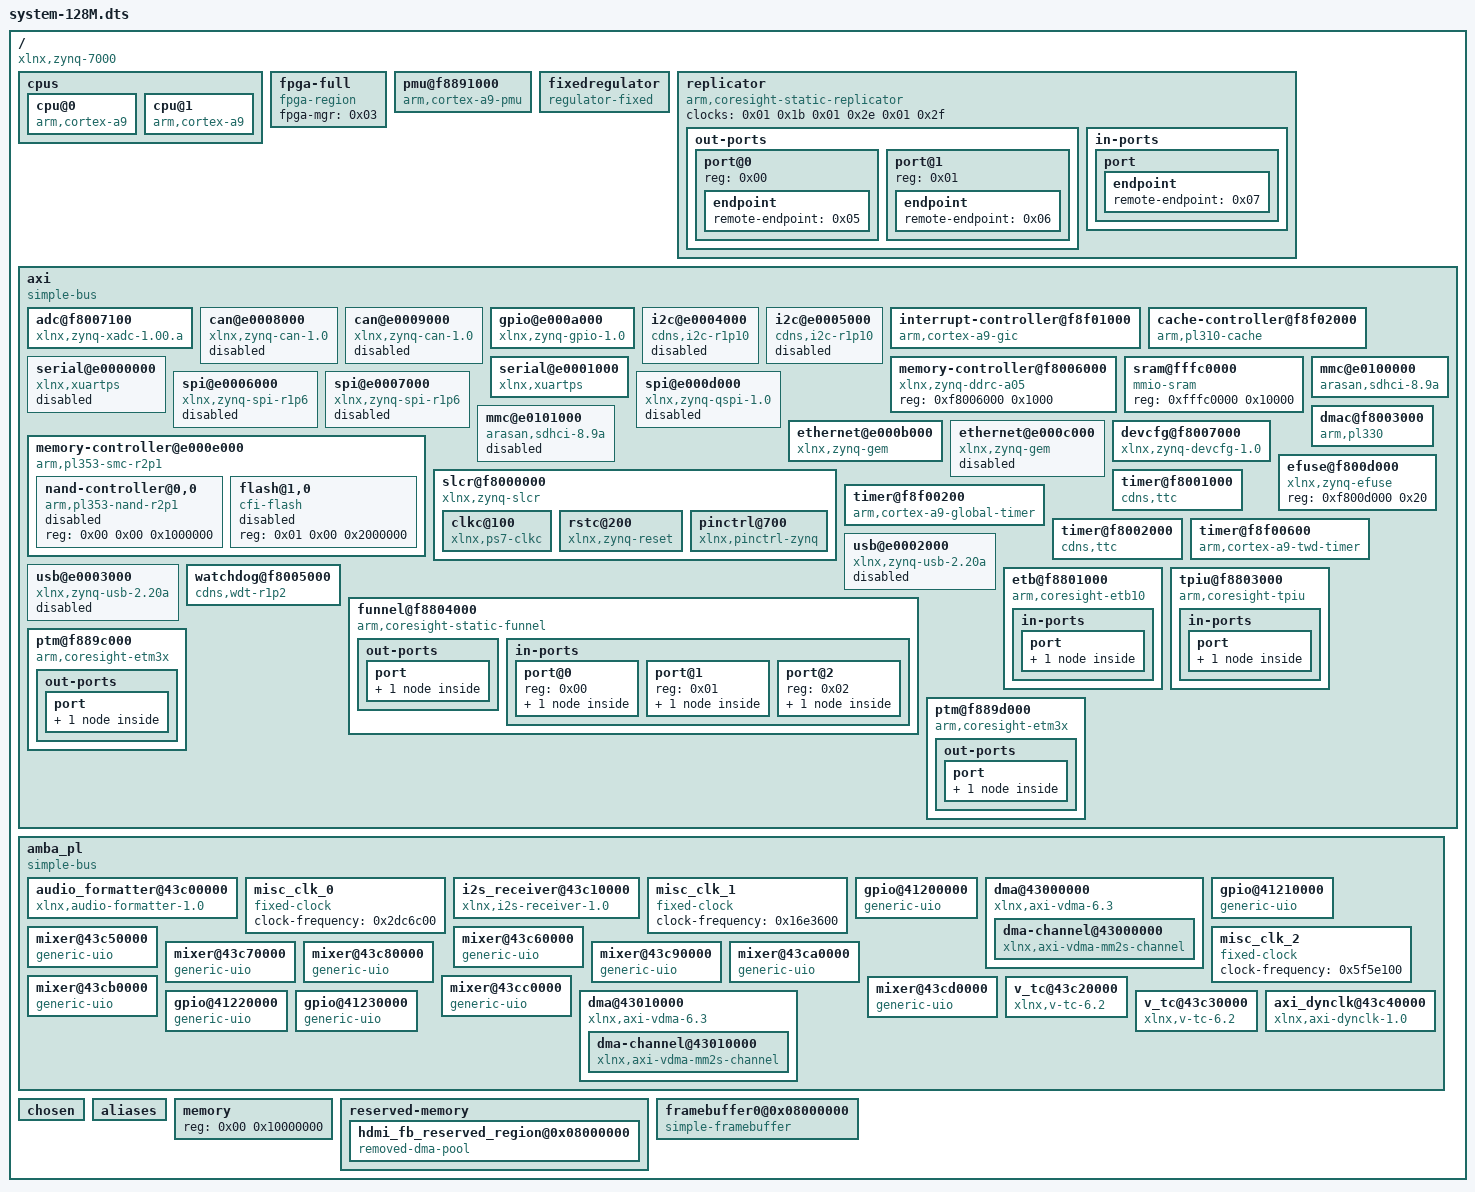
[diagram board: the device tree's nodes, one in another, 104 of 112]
/dts-v1/;

/ {
	#address-cells = <0x01>;
	#size-cells = <0x01>;
	compatible = "xlnx,zynq-7000";

	cpus {
		#address-cells = <0x01>;
		#size-cells = <0x00>;

		cpu@0 {
			compatible = "arm,cortex-a9";
			device_type = "cpu";
			reg = <0x00>;
			clocks = <0x01 0x03>;
			clock-latency = <0x3e8>;
			cpu0-supply = <0x02>;
			operating-points = <0xa2c2a 0xf4240 0x51615 0xf4240>;
			phandle = <0x0e>;
		};

		cpu@1 {
			compatible = "arm,cortex-a9";
			device_type = "cpu";
			reg = <0x01>;
			clocks = <0x01 0x03>;
			phandle = <0x10>;
		};
	};

	fpga-full {
		compatible = "fpga-region";
		fpga-mgr = <0x03>;
		#address-cells = <0x01>;
		#size-cells = <0x01>;
		ranges;
		phandle = <0x17>;
	};

	pmu@f8891000 {
		compatible = "arm,cortex-a9-pmu";
		interrupts = <0x00 0x05 0x04 0x00 0x06 0x04>;
		interrupt-parent = <0x04>;
		reg = <0xf8891000 0x1000 0xf8893000 0x1000>;
	};

	fixedregulator {
		compatible = "regulator-fixed";
		regulator-name = "VCCPINT";
		regulator-min-microvolt = <0xf4240>;
		regulator-max-microvolt = <0xf4240>;
		regulator-boot-on;
		regulator-always-on;
		phandle = <0x02>;
	};

	replicator {
		compatible = "arm,coresight-static-replicator";
		clocks = <0x01 0x1b 0x01 0x2e 0x01 0x2f>;
		clock-names = "apb_pclk\0dbg_trc\0dbg_apb";

		out-ports {
			#address-cells = <0x01>;
			#size-cells = <0x00>;

			port@0 {
				reg = <0x00>;

				endpoint {
					remote-endpoint = <0x05>;
					phandle = <0x0a>;
				};
			};

			port@1 {
				reg = <0x01>;

				endpoint {
					remote-endpoint = <0x06>;
					phandle = <0x09>;
				};
			};
		};

		in-ports {

			port {

				endpoint {
					remote-endpoint = <0x07>;
					phandle = <0x0b>;
				};
			};
		};
	};

	axi {
		u-boot,dm-pre-reloc;
		compatible = "simple-bus";
		#address-cells = <0x01>;
		#size-cells = <0x01>;
		interrupt-parent = <0x04>;
		ranges;
		phandle = <0x18>;

		adc@f8007100 {
			compatible = "xlnx,zynq-xadc-1.00.a";
			reg = <0xf8007100 0x20>;
			interrupts = <0x00 0x07 0x04>;
			interrupt-parent = <0x04>;
			clocks = <0x01 0x0c>;
			phandle = <0x19>;
		};

		can@e0008000 {
			compatible = "xlnx,zynq-can-1.0";
			status = "disabled";
			clocks = <0x01 0x13 0x01 0x24>;
			clock-names = "can_clk\0pclk";
			reg = <0xe0008000 0x1000>;
			interrupts = <0x00 0x1c 0x04>;
			interrupt-parent = <0x04>;
			tx-fifo-depth = <0x40>;
			rx-fifo-depth = <0x40>;
			phandle = <0x1a>;
		};

		can@e0009000 {
			compatible = "xlnx,zynq-can-1.0";
			status = "disabled";
			clocks = <0x01 0x14 0x01 0x25>;
			clock-names = "can_clk\0pclk";
			reg = <0xe0009000 0x1000>;
			interrupts = <0x00 0x33 0x04>;
			interrupt-parent = <0x04>;
			tx-fifo-depth = <0x40>;
			rx-fifo-depth = <0x40>;
			phandle = <0x1b>;
		};

		gpio@e000a000 {
			compatible = "xlnx,zynq-gpio-1.0";
			#gpio-cells = <0x02>;
			clocks = <0x01 0x2a>;
			gpio-controller;
			interrupt-controller;
			#interrupt-cells = <0x02>;
			interrupt-parent = <0x04>;
			interrupts = <0x00 0x14 0x04>;
			reg = <0xe000a000 0x1000>;
			emio-gpio-width = <0x40>;
			gpio-mask-high = <0x00>;
			gpio-mask-low = <0x5600>;
			phandle = <0x1c>;
		};

		i2c@e0004000 {
			compatible = "cdns,i2c-r1p10";
			status = "disabled";
			clocks = <0x01 0x26>;
			interrupt-parent = <0x04>;
			interrupts = <0x00 0x19 0x04>;
			reg = <0xe0004000 0x1000>;
			#address-cells = <0x01>;
			#size-cells = <0x00>;
			phandle = <0x1d>;
		};

		i2c@e0005000 {
			compatible = "cdns,i2c-r1p10";
			status = "disabled";
			clocks = <0x01 0x27>;
			interrupt-parent = <0x04>;
			interrupts = <0x00 0x30 0x04>;
			reg = <0xe0005000 0x1000>;
			#address-cells = <0x01>;
			#size-cells = <0x00>;
			phandle = <0x1e>;
		};

		interrupt-controller@f8f01000 {
			compatible = "arm,cortex-a9-gic";
			#interrupt-cells = <0x03>;
			interrupt-controller;
			reg = <0xf8f01000 0x1000 0xf8f00100 0x100>;
			num_cpus = <0x02>;
			num_interrupts = <0x60>;
			phandle = <0x04>;
		};

		cache-controller@f8f02000 {
			compatible = "arm,pl310-cache";
			reg = <0xf8f02000 0x1000>;
			interrupts = <0x00 0x02 0x04>;
			arm,data-latency = <0x03 0x02 0x02>;
			arm,tag-latency = <0x02 0x02 0x02>;
			cache-unified;
			cache-level = <0x02>;
			phandle = <0x1f>;
		};

		memory-controller@f8006000 {
			compatible = "xlnx,zynq-ddrc-a05";
			reg = <0xf8006000 0x1000>;
			phandle = <0x20>;
		};

		sram@fffc0000 {
			compatible = "mmio-sram";
			reg = <0xfffc0000 0x10000>;
			phandle = <0x21>;
		};

		serial@e0000000 {
			compatible = "xlnx,xuartps\0cdns,uart-r1p8";
			status = "disabled";
			clocks = <0x01 0x17 0x01 0x28>;
			clock-names = "uart_clk\0pclk";
			reg = <0xe0000000 0x1000>;
			interrupts = <0x00 0x1b 0x04>;
			phandle = <0x22>;
		};

		serial@e0001000 {
			compatible = "xlnx,xuartps\0cdns,uart-r1p8";
			status = "okay";
			clocks = <0x01 0x18 0x01 0x29>;
			clock-names = "uart_clk\0pclk";
			reg = <0xe0001000 0x1000>;
			interrupts = <0x00 0x32 0x04>;
			cts-override;
			device_type = "serial";
			port-number = <0x00>;
			phandle = <0x23>;
		};

		spi@e0006000 {
			compatible = "xlnx,zynq-spi-r1p6";
			reg = <0xe0006000 0x1000>;
			status = "disabled";
			interrupt-parent = <0x04>;
			interrupts = <0x00 0x1a 0x04>;
			clocks = <0x01 0x19 0x01 0x22>;
			clock-names = "ref_clk\0pclk";
			#address-cells = <0x01>;
			#size-cells = <0x00>;
			phandle = <0x24>;
		};

		spi@e0007000 {
			compatible = "xlnx,zynq-spi-r1p6";
			reg = <0xe0007000 0x1000>;
			status = "disabled";
			interrupt-parent = <0x04>;
			interrupts = <0x00 0x31 0x04>;
			clocks = <0x01 0x1a 0x01 0x23>;
			clock-names = "ref_clk\0pclk";
			#address-cells = <0x01>;
			#size-cells = <0x00>;
			phandle = <0x25>;
		};

		spi@e000d000 {
			clock-names = "ref_clk\0pclk";
			clocks = <0x01 0x0a 0x01 0x2b>;
			compatible = "xlnx,zynq-qspi-1.0";
			status = "disabled";
			interrupt-parent = <0x04>;
			interrupts = <0x00 0x13 0x04>;
			reg = <0xe000d000 0x1000>;
			#address-cells = <0x01>;
			#size-cells = <0x00>;
			phandle = <0x26>;
		};

		ethernet@e000b000 {
			compatible = "xlnx,zynq-gem\0cdns,zynq-gem\0cdns,gem";
			reg = <0xe000b000 0x1000>;
			status = "okay";
			interrupts = <0x00 0x16 0x04>;
			clocks = <0x01 0x1e 0x01 0x1e 0x01 0x0d>;
			clock-names = "pclk\0hclk\0tx_clk";
			#address-cells = <0x01>;
			#size-cells = <0x00>;
			phy-mode = "gmii";
			xlnx,ptp-enet-clock = <0x69f6bcb>;
			local-mac-address = [00 0a 35 00 1e 53];
			phandle = <0x27>;
		};

		ethernet@e000c000 {
			compatible = "xlnx,zynq-gem\0cdns,zynq-gem\0cdns,gem";
			reg = <0xe000c000 0x1000>;
			status = "disabled";
			interrupts = <0x00 0x2d 0x04>;
			clocks = <0x01 0x1f 0x01 0x1f 0x01 0x0e>;
			clock-names = "pclk\0hclk\0tx_clk";
			#address-cells = <0x01>;
			#size-cells = <0x00>;
			phandle = <0x28>;
		};

		memory-controller@e000e000 {
			compatible = "arm,pl353-smc-r2p1\0arm,primecell";
			reg = <0xe000e000 0x1000>;
			status = "okay";
			clock-names = "memclk\0apb_pclk";
			clocks = <0x01 0x0b 0x01 0x2c>;
			ranges = <0x00 0x00 0xe1000000 0x1000000 0x01 0x00 0xe2000000 0x2000000 0x02 0x00 0xe4000000 0x2000000>;
			#address-cells = <0x02>;
			#size-cells = <0x01>;
			interrupt-parent = <0x04>;
			interrupts = <0x00 0x12 0x04>;
			phandle = <0x29>;

			nand-controller@0,0 {
				compatible = "arm,pl353-nand-r2p1";
				reg = <0x00 0x00 0x1000000>;
				status = "disabled";
				#address-cells = <0x01>;
				#size-cells = <0x00>;
				phandle = <0x2a>;
			};

			flash@1,0 {
				status = "disabled";
				compatible = "cfi-flash";
				reg = <0x01 0x00 0x2000000>;
				#address-cells = <0x01>;
				#size-cells = <0x01>;
				phandle = <0x2b>;
			};
		};

		mmc@e0100000 {
			compatible = "arasan,sdhci-8.9a";
			status = "okay";
			clock-names = "clk_xin\0clk_ahb";
			clocks = <0x01 0x15 0x01 0x20>;
			interrupt-parent = <0x04>;
			interrupts = <0x00 0x18 0x04>;
			reg = <0xe0100000 0x1000>;
			xlnx,has-cd = <0x01>;
			xlnx,has-power = <0x00>;
			xlnx,has-wp = <0x00>;
			phandle = <0x2c>;
		};

		mmc@e0101000 {
			compatible = "arasan,sdhci-8.9a";
			status = "disabled";
			clock-names = "clk_xin\0clk_ahb";
			clocks = <0x01 0x16 0x01 0x21>;
			interrupt-parent = <0x04>;
			interrupts = <0x00 0x2f 0x04>;
			reg = <0xe0101000 0x1000>;
			phandle = <0x2d>;
		};

		slcr@f8000000 {
			u-boot,dm-pre-reloc;
			#address-cells = <0x01>;
			#size-cells = <0x01>;
			compatible = "xlnx,zynq-slcr\0syscon\0simple-mfd";
			reg = <0xf8000000 0x1000>;
			ranges;
			phandle = <0x08>;

			clkc@100 {
				u-boot,dm-pre-reloc;
				#clock-cells = <0x01>;
				compatible = "xlnx,ps7-clkc";
				fclk-enable = <0x07>;
				clock-output-names = "armpll\0ddrpll\0iopll\0cpu_6or4x\0cpu_3or2x\0cpu_2x\0cpu_1x\0ddr2x\0ddr3x\0dci\0lqspi\0smc\0pcap\0gem0\0gem1\0fclk0\0fclk1\0fclk2\0fclk3\0can0\0can1\0sdio0\0sdio1\0uart0\0uart1\0spi0\0spi1\0dma\0usb0_aper\0usb1_aper\0gem0_aper\0gem1_aper\0sdio0_aper\0sdio1_aper\0spi0_aper\0spi1_aper\0can0_aper\0can1_aper\0i2c0_aper\0i2c1_aper\0uart0_aper\0uart1_aper\0gpio_aper\0lqspi_aper\0smc_aper\0swdt\0dbg_trc\0dbg_apb";
				reg = <0x100 0x100>;
				ps-clk-frequency = <0x1fca055>;
				phandle = <0x01>;
			};

			rstc@200 {
				compatible = "xlnx,zynq-reset";
				reg = <0x200 0x48>;
				#reset-cells = <0x01>;
				syscon = <0x08>;
				phandle = <0x2e>;
			};

			pinctrl@700 {
				compatible = "xlnx,pinctrl-zynq";
				reg = <0x700 0x200>;
				syscon = <0x08>;
				phandle = <0x2f>;
			};
		};

		dmac@f8003000 {
			compatible = "arm,pl330\0arm,primecell";
			reg = <0xf8003000 0x1000>;
			interrupt-parent = <0x04>;
			interrupt-names = "abort\0dma0\0dma1\0dma2\0dma3\0dma4\0dma5\0dma6\0dma7";
			interrupts = <0x00 0x0d 0x04 0x00 0x0e 0x04 0x00 0x0f 0x04 0x00 0x10 0x04 0x00 0x11 0x04 0x00 0x28 0x04 0x00 0x29 0x04 0x00 0x2a 0x04 0x00 0x2b 0x04>;
			#dma-cells = <0x01>;
			#dma-channels = <0x08>;
			#dma-requests = <0x04>;
			clocks = <0x01 0x1b>;
			clock-names = "apb_pclk";
			phandle = <0x30>;
		};

		devcfg@f8007000 {
			compatible = "xlnx,zynq-devcfg-1.0";
			interrupt-parent = <0x04>;
			interrupts = <0x00 0x08 0x04>;
			reg = <0xf8007000 0x100>;
			clocks = <0x01 0x0c 0x01 0x0f 0x01 0x10 0x01 0x11 0x01 0x12>;
			clock-names = "ref_clk\0fclk0\0fclk1\0fclk2\0fclk3";
			syscon = <0x08>;
			phandle = <0x03>;
		};

		efuse@f800d000 {
			compatible = "xlnx,zynq-efuse";
			reg = <0xf800d000 0x20>;
			phandle = <0x31>;
		};

		timer@f8f00200 {
			compatible = "arm,cortex-a9-global-timer";
			reg = <0xf8f00200 0x20>;
			interrupts = <0x01 0x0b 0x301>;
			interrupt-parent = <0x04>;
			clocks = <0x01 0x04>;
			phandle = <0x32>;
		};

		timer@f8001000 {
			interrupt-parent = <0x04>;
			interrupts = <0x00 0x0a 0x04 0x00 0x0b 0x04 0x00 0x0c 0x04>;
			compatible = "cdns,ttc";
			clocks = <0x01 0x06>;
			reg = <0xf8001000 0x1000>;
			phandle = <0x33>;
		};

		timer@f8002000 {
			interrupt-parent = <0x04>;
			interrupts = <0x00 0x25 0x04 0x00 0x26 0x04 0x00 0x27 0x04>;
			compatible = "cdns,ttc";
			clocks = <0x01 0x06>;
			reg = <0xf8002000 0x1000>;
			phandle = <0x34>;
		};

		timer@f8f00600 {
			interrupt-parent = <0x04>;
			interrupts = <0x01 0x0d 0x301>;
			compatible = "arm,cortex-a9-twd-timer";
			reg = <0xf8f00600 0x20>;
			clocks = <0x01 0x04>;
			phandle = <0x35>;
		};

		usb@e0002000 {
			compatible = "xlnx,zynq-usb-2.20a\0chipidea,usb2";
			status = "disabled";
			clocks = <0x01 0x1c>;
			interrupt-parent = <0x04>;
			interrupts = <0x00 0x15 0x04>;
			reg = <0xe0002000 0x1000>;
			phy_type = "ulpi";
			phandle = <0x36>;
		};

		usb@e0003000 {
			compatible = "xlnx,zynq-usb-2.20a\0chipidea,usb2";
			status = "disabled";
			clocks = <0x01 0x1d>;
			interrupt-parent = <0x04>;
			interrupts = <0x00 0x2c 0x04>;
			reg = <0xe0003000 0x1000>;
			phy_type = "ulpi";
			phandle = <0x37>;
		};

		watchdog@f8005000 {
			clocks = <0x01 0x2d>;
			compatible = "cdns,wdt-r1p2";
			interrupt-parent = <0x04>;
			interrupts = <0x00 0x09 0x01>;
			reg = <0xf8005000 0x1000>;
			timeout-sec = <0x0a>;
			phandle = <0x38>;
		};

		etb@f8801000 {
			compatible = "arm,coresight-etb10\0arm,primecell";
			reg = <0xf8801000 0x1000>;
			clocks = <0x01 0x1b 0x01 0x2e 0x01 0x2f>;
			clock-names = "apb_pclk\0dbg_trc\0dbg_apb";

			in-ports {

				port {

					endpoint {
						remote-endpoint = <0x09>;
						phandle = <0x06>;
					};
				};
			};
		};

		tpiu@f8803000 {
			compatible = "arm,coresight-tpiu\0arm,primecell";
			reg = <0xf8803000 0x1000>;
			clocks = <0x01 0x1b 0x01 0x2e 0x01 0x2f>;
			clock-names = "apb_pclk\0dbg_trc\0dbg_apb";

			in-ports {

				port {

					endpoint {
						remote-endpoint = <0x0a>;
						phandle = <0x05>;
					};
				};
			};
		};

		funnel@f8804000 {
			compatible = "arm,coresight-static-funnel\0arm,primecell";
			reg = <0xf8804000 0x1000>;
			clocks = <0x01 0x1b 0x01 0x2e 0x01 0x2f>;
			clock-names = "apb_pclk\0dbg_trc\0dbg_apb";

			out-ports {

				port {

					endpoint {
						remote-endpoint = <0x0b>;
						phandle = <0x07>;
					};
				};
			};

			in-ports {
				#address-cells = <0x01>;
				#size-cells = <0x00>;

				port@0 {
					reg = <0x00>;

					endpoint {
						remote-endpoint = <0x0c>;
						phandle = <0x0f>;
					};
				};

				port@1 {
					reg = <0x01>;

					endpoint {
						remote-endpoint = <0x0d>;
						phandle = <0x11>;
					};
				};

				port@2 {
					reg = <0x02>;

					endpoint {
						phandle = <0x39>;
					};
				};
			};
		};

		ptm@f889c000 {
			compatible = "arm,coresight-etm3x\0arm,primecell";
			reg = <0xf889c000 0x1000>;
			clocks = <0x01 0x1b 0x01 0x2e 0x01 0x2f>;
			clock-names = "apb_pclk\0dbg_trc\0dbg_apb";
			cpu = <0x0e>;

			out-ports {

				port {

					endpoint {
						remote-endpoint = <0x0f>;
						phandle = <0x0c>;
					};
				};
			};
		};

		ptm@f889d000 {
			compatible = "arm,coresight-etm3x\0arm,primecell";
			reg = <0xf889d000 0x1000>;
			clocks = <0x01 0x1b 0x01 0x2e 0x01 0x2f>;
			clock-names = "apb_pclk\0dbg_trc\0dbg_apb";
			cpu = <0x10>;

			out-ports {

				port {

					endpoint {
						remote-endpoint = <0x11>;
						phandle = <0x0d>;
					};
				};
			};
		};
	};

	amba_pl {
		#address-cells = <0x01>;
		#size-cells = <0x01>;
		compatible = "simple-bus";
		ranges;
		phandle = <0x3a>;

		audio_formatter@43c00000 {
			clock-names = "s_axi_lite_aclk\0s_axis_s2mm_aclk";
			clocks = <0x01 0x0f 0x12>;
			compatible = "xlnx,audio-formatter-1.0\0xlnx,audio-formatter-1.0";
			interrupt-names = "irq_s2mm";
			interrupt-parent = <0x04>;
			interrupts = <0x00 0x24 0x04>;
			reg = <0x43c00000 0x10000>;
			xlnx,include-mm2s = <0x00>;
			xlnx,include-s2mm = <0x01>;
			xlnx,max-num-channels-mm2s = <0x02>;
			xlnx,max-num-channels-s2mm = <0x02>;
			xlnx,mm2s-addr-width = <0x40>;
			xlnx,mm2s-async-clock = <0x01>;
			xlnx,mm2s-dataformat = <0x03>;
			xlnx,packing-mode-mm2s = <0x00>;
			xlnx,packing-mode-s2mm = <0x00>;
			xlnx,rx = <0x13>;
			xlnx,s2mm-addr-width = <0x40>;
			xlnx,s2mm-async-clock = <0x01>;
			xlnx,s2mm-dataformat = <0x01>;
			phandle = <0x15>;
		};

		misc_clk_0 {
			#clock-cells = <0x00>;
			clock-frequency = <0x2dc6c00>;
			compatible = "fixed-clock";
			phandle = <0x12>;
		};

		i2s_receiver@43c10000 {
			aud_mclk = <0x16e3600>;
			clock-names = "s_axi_ctrl_aclk\0aud_mclk\0m_axis_aud_aclk";
			clocks = <0x01 0x0f 0x14 0x12>;
			compatible = "xlnx,i2s-receiver-1.0\0xlnx,i2s-receiver-1.0";
			interrupt-names = "irq";
			interrupt-parent = <0x04>;
			interrupts = <0x00 0x23 0x04>;
			reg = <0x43c10000 0x10000>;
			xlnx,depth = <0x100>;
			xlnx,dwidth = <0x10>;
			xlnx,num-channels = <0x01>;
			xlnx,snd-pcm = <0x15>;
			phandle = <0x13>;
		};

		misc_clk_1 {
			#clock-cells = <0x00>;
			clock-frequency = <0x16e3600>;
			compatible = "fixed-clock";
			phandle = <0x14>;
		};

		gpio@41200000 {
			#gpio-cells = <0x02>;
			#interrupt-cells = <0x02>;
			clock-names = "s_axi_aclk";
			clocks = <0x01 0x0f>;
			compatible = "generic-uio";
			gpio-controller;
			interrupt-controller;
			interrupt-names = "ip2intc_irpt";
			interrupt-parent = <0x04>;
			interrupts = <0x00 0x22 0x04>;
			reg = <0x41200000 0x10000>;
			xlnx,all-inputs = <0x01>;
			xlnx,all-inputs-2 = <0x00>;
			xlnx,all-outputs = <0x00>;
			xlnx,all-outputs-2 = <0x00>;
			xlnx,dout-default = <0x00>;
			xlnx,dout-default-2 = <0x00>;
			xlnx,gpio-width = <0x01>;
			xlnx,gpio2-width = <0x20>;
			xlnx,interrupt-present = <0x01>;
			xlnx,is-dual = <0x00>;
			xlnx,tri-default = <0xffffffff>;
			xlnx,tri-default-2 = <0xffffffff>;
			phandle = <0x3b>;
		};

		dma@43000000 {
			#dma-cells = <0x01>;
			clock-names = "s_axi_lite_aclk\0m_axi_mm2s_aclk\0m_axis_mm2s_aclk";
			clocks = <0x01 0x0f 0x01 0x11 0x01 0x11>;
			compatible = "xlnx,axi-vdma-6.3\0xlnx,axi-vdma-1.00.a";
			interrupt-names = "mm2s_introut";
			interrupt-parent = <0x04>;
			interrupts = <0x00 0x21 0x04>;
			reg = <0x43000000 0x10000>;
			xlnx,addrwidth = <0x20>;
			xlnx,flush-fsync = <0x01>;
			xlnx,num-fstores = <0x03>;
			phandle = <0x3c>;

			dma-channel@43000000 {
				compatible = "xlnx,axi-vdma-mm2s-channel";
				interrupts = <0x00 0x21 0x04>;
				xlnx,datawidth = <0x20>;
				xlnx,device-id = <0x00>;
				xlnx,genlock-mode;
			};
		};

		gpio@41210000 {
			#gpio-cells = <0x02>;
			clock-names = "s_axi_aclk";
			clocks = <0x01 0x0f>;
			compatible = "generic-uio";
			gpio-controller;
			reg = <0x41210000 0x10000>;
			xlnx,all-inputs = <0x00>;
			xlnx,all-inputs-2 = <0x00>;
			xlnx,all-outputs = <0x01>;
			xlnx,all-outputs-2 = <0x00>;
			xlnx,dout-default = <0xffffffff>;
			xlnx,dout-default-2 = <0x00>;
			xlnx,gpio-width = <0x18>;
			xlnx,gpio2-width = <0x20>;
			xlnx,interrupt-present = <0x00>;
			xlnx,is-dual = <0x00>;
			xlnx,tri-default = <0xffffffff>;
			xlnx,tri-default-2 = <0xffffffff>;
			phandle = <0x3d>;
		};

		mixer@43c50000 {
			clock-names = "pix_clk\0s00_axi_aclk";
			clocks = <0x16 0x01 0x0f>;
			compatible = "generic-uio";
			reg = <0x43c50000 0x10000>;
			xlnx,s00-axi-addr-width = <0x06>;
			xlnx,s00-axi-data-width = <0x20>;
			phandle = <0x3e>;
		};

		misc_clk_2 {
			#clock-cells = <0x00>;
			clock-frequency = <0x5f5e100>;
			compatible = "fixed-clock";
			phandle = <0x16>;
		};

		mixer@43c60000 {
			clock-names = "pix_clk\0s00_axi_aclk";
			clocks = <0x16 0x01 0x0f>;
			compatible = "generic-uio";
			reg = <0x43c60000 0x10000>;
			xlnx,s00-axi-addr-width = <0x06>;
			xlnx,s00-axi-data-width = <0x20>;
			phandle = <0x3f>;
		};

		mixer@43c70000 {
			clock-names = "pix_clk\0s00_axi_aclk";
			clocks = <0x16 0x01 0x0f>;
			compatible = "generic-uio";
			reg = <0x43c70000 0x10000>;
			xlnx,s00-axi-addr-width = <0x06>;
			xlnx,s00-axi-data-width = <0x20>;
			phandle = <0x40>;
		};

		mixer@43c80000 {
			clock-names = "pix_clk\0s00_axi_aclk";
			clocks = <0x16 0x01 0x0f>;
			compatible = "generic-uio";
			reg = <0x43c80000 0x10000>;
			xlnx,s00-axi-addr-width = <0x06>;
			xlnx,s00-axi-data-width = <0x20>;
			phandle = <0x41>;
		};

		mixer@43c90000 {
			clock-names = "pix_clk\0s00_axi_aclk";
			clocks = <0x16 0x01 0x0f>;
			compatible = "generic-uio";
			reg = <0x43c90000 0x10000>;
			xlnx,s00-axi-addr-width = <0x06>;
			xlnx,s00-axi-data-width = <0x20>;
			phandle = <0x42>;
		};

		mixer@43ca0000 {
			clock-names = "pix_clk\0s00_axi_aclk";
			clocks = <0x16 0x01 0x0f>;
			compatible = "generic-uio";
			reg = <0x43ca0000 0x10000>;
			xlnx,s00-axi-addr-width = <0x06>;
			xlnx,s00-axi-data-width = <0x20>;
			phandle = <0x43>;
		};

		mixer@43cb0000 {
			clock-names = "pix_clk\0s00_axi_aclk";
			clocks = <0x16 0x01 0x0f>;
			compatible = "generic-uio";
			reg = <0x43cb0000 0x10000>;
			xlnx,s00-axi-addr-width = <0x06>;
			xlnx,s00-axi-data-width = <0x20>;
			phandle = <0x44>;
		};

		mixer@43cc0000 {
			clock-names = "pix_clk\0s00_axi_aclk";
			clocks = <0x16 0x01 0x0f>;
			compatible = "generic-uio";
			reg = <0x43cc0000 0x10000>;
			xlnx,s00-axi-addr-width = <0x06>;
			xlnx,s00-axi-data-width = <0x20>;
			phandle = <0x45>;
		};

		mixer@43cd0000 {
			clock-names = "pix_clk\0s00_axi_aclk";
			clocks = <0x16 0x01 0x0f>;
			compatible = "generic-uio";
			reg = <0x43cd0000 0x10000>;
			xlnx,s00-axi-addr-width = <0x06>;
			xlnx,s00-axi-data-width = <0x20>;
			phandle = <0x46>;
		};

		v_tc@43c20000 {
			clock-names = "clk\0s_axi_aclk";
			clocks = <0x16 0x01 0x0f>;
			compatible = "xlnx,v-tc-6.2\0xlnx,v-tc-6.1";
			interrupt-names = "irq";
			interrupt-parent = <0x04>;
			interrupts = <0x00 0x20 0x04>;
			reg = <0x43c20000 0x10000>;
			xlnx,generator;
			phandle = <0x47>;
		};

		gpio@41220000 {
			#gpio-cells = <0x02>;
			#interrupt-cells = <0x02>;
			clock-names = "s_axi_aclk";
			clocks = <0x01 0x0f>;
			compatible = "generic-uio";
			gpio-controller;
			interrupt-controller;
			interrupt-names = "ip2intc_irpt";
			interrupt-parent = <0x04>;
			interrupts = <0x00 0x1f 0x04>;
			reg = <0x41220000 0x10000>;
			xlnx,all-inputs = <0x01>;
			xlnx,all-inputs-2 = <0x00>;
			xlnx,all-outputs = <0x00>;
			xlnx,all-outputs-2 = <0x00>;
			xlnx,dout-default = <0x00>;
			xlnx,dout-default-2 = <0x00>;
			xlnx,gpio-width = <0x01>;
			xlnx,gpio2-width = <0x20>;
			xlnx,interrupt-present = <0x01>;
			xlnx,is-dual = <0x00>;
			xlnx,tri-default = <0xffffffff>;
			xlnx,tri-default-2 = <0xffffffff>;
			phandle = <0x48>;
		};

		dma@43010000 {
			#dma-cells = <0x01>;
			clock-names = "s_axi_lite_aclk\0m_axi_mm2s_aclk\0m_axis_mm2s_aclk";
			clocks = <0x01 0x0f 0x01 0x11 0x01 0x11>;
			compatible = "xlnx,axi-vdma-6.3\0xlnx,axi-vdma-1.00.a";
			interrupt-names = "mm2s_introut";
			interrupt-parent = <0x04>;
			interrupts = <0x00 0x1e 0x04>;
			reg = <0x43010000 0x10000>;
			xlnx,addrwidth = <0x20>;
			xlnx,flush-fsync = <0x01>;
			xlnx,num-fstores = <0x03>;
			phandle = <0x49>;

			dma-channel@43010000 {
				compatible = "xlnx,axi-vdma-mm2s-channel";
				interrupts = <0x00 0x1e 0x04>;
				xlnx,datawidth = <0x20>;
				xlnx,device-id = <0x01>;
				xlnx,genlock-mode;
			};
		};

		gpio@41230000 {
			#gpio-cells = <0x02>;
			clock-names = "s_axi_aclk";
			clocks = <0x01 0x0f>;
			compatible = "generic-uio";
			gpio-controller;
			reg = <0x41230000 0x10000>;
			xlnx,all-inputs = <0x00>;
			xlnx,all-inputs-2 = <0x00>;
			xlnx,all-outputs = <0x01>;
			xlnx,all-outputs-2 = <0x00>;
			xlnx,dout-default = <0xffffff>;
			xlnx,dout-default-2 = <0x00>;
			xlnx,gpio-width = <0x18>;
			xlnx,gpio2-width = <0x20>;
			xlnx,interrupt-present = <0x00>;
			xlnx,is-dual = <0x00>;
			xlnx,tri-default = <0xffffffff>;
			xlnx,tri-default-2 = <0xffffffff>;
			phandle = <0x4a>;
		};

		v_tc@43c30000 {
			clock-names = "clk\0s_axi_aclk";
			clocks = <0x16 0x01 0x0f>;
			compatible = "xlnx,v-tc-6.2\0xlnx,v-tc-6.1";
			interrupt-names = "irq";
			interrupt-parent = <0x04>;
			interrupts = <0x00 0x1d 0x04>;
			reg = <0x43c30000 0x10000>;
			xlnx,generator;
			phandle = <0x4b>;
		};

		axi_dynclk@43c40000 {
			clock-names = "REF_CLK_I\0s00_axi_aclk";
			clocks = <0x01 0x0f 0x01 0x0f>;
			compatible = "xlnx,axi-dynclk-1.0";
			reg = <0x43c40000 0x10000>;
			xlnx,s00-axi-addr-width = <0x05>;
			xlnx,s00-axi-data-width = <0x20>;
			phandle = <0x4c>;
		};
	};

	chosen {
		bootargs = "earlycon console=ttyPS0,115200 clk_ignore_unused root=/dev/mmcblk0p2 rw rootwait cma=256M uio_pdrv_genirq.of_id=generic-uio";
		stdout-path = "serial0:115200n8";
	};

	aliases {
		ethernet0 = "/axi/ethernet@e000b000";
		serial0 = "/axi/serial@e0001000";
	};

	memory {
		device_type = "memory";
		reg = <0x00 0x10000000>;
	};

	reserved-memory {
		#address-cells = <0x01>;
		#size-cells = <0x01>;
		ranges;

		hdmi_fb_reserved_region@0x08000000 {
			compatible = "removed-dma-pool";
			no-map;
			reg = <0x8000000 0x8000000>;
		};
	};

	framebuffer0@0x08000000 {
		compatible = "simple-framebuffer";
		reg = <0x8000000 0xa8c000>;
		width = <0x500>;
		height = <0x870>;
		stride = <0x1400>;
		format = "a8r8g8b8";
		status = "okay";
		phandle = <0x4d>;
	};

	__symbols__ {
		cpu0 = "/cpus/cpu@0";
		cpu1 = "/cpus/cpu@1";
		fpga_full = "/fpga-full";
		regulator_vccpint = "/fixedregulator";
		replicator_out_port0 = "/replicator/out-ports/port@0/endpoint";
		replicator_out_port1 = "/replicator/out-ports/port@1/endpoint";
		replicator_in_port0 = "/replicator/in-ports/port/endpoint";
		amba = "/axi";
		adc = "/axi/adc@f8007100";
		can0 = "/axi/can@e0008000";
		can1 = "/axi/can@e0009000";
		gpio0 = "/axi/gpio@e000a000";
		i2c0 = "/axi/i2c@e0004000";
		i2c1 = "/axi/i2c@e0005000";
		intc = "/axi/interrupt-controller@f8f01000";
		L2 = "/axi/cache-controller@f8f02000";
		mc = "/axi/memory-controller@f8006000";
		ocm = "/axi/sram@fffc0000";
		uart0 = "/axi/serial@e0000000";
		uart1 = "/axi/serial@e0001000";
		spi0 = "/axi/spi@e0006000";
		spi1 = "/axi/spi@e0007000";
		qspi = "/axi/spi@e000d000";
		gem0 = "/axi/ethernet@e000b000";
		gem1 = "/axi/ethernet@e000c000";
		smcc = "/axi/memory-controller@e000e000";
		nfc0 = "/axi/memory-controller@e000e000/nand-controller@0,0";
		nor0 = "/axi/memory-controller@e000e000/flash@1,0";
		sdhci0 = "/axi/mmc@e0100000";
		sdhci1 = "/axi/mmc@e0101000";
		slcr = "/axi/slcr@f8000000";
		clkc = "/axi/slcr@f8000000/clkc@100";
		rstc = "/axi/slcr@f8000000/rstc@200";
		pinctrl0 = "/axi/slcr@f8000000/pinctrl@700";
		dmac_s = "/axi/dmac@f8003000";
		devcfg = "/axi/devcfg@f8007000";
		efuse = "/axi/efuse@f800d000";
		global_timer = "/axi/timer@f8f00200";
		ttc0 = "/axi/timer@f8001000";
		ttc1 = "/axi/timer@f8002000";
		scutimer = "/axi/timer@f8f00600";
		usb0 = "/axi/usb@e0002000";
		usb1 = "/axi/usb@e0003000";
		watchdog0 = "/axi/watchdog@f8005000";
		etb_in_port = "/axi/etb@f8801000/in-ports/port/endpoint";
		tpiu_in_port = "/axi/tpiu@f8803000/in-ports/port/endpoint";
		funnel_out_port = "/axi/funnel@f8804000/out-ports/port/endpoint";
		funnel0_in_port0 = "/axi/funnel@f8804000/in-ports/port@0/endpoint";
		funnel0_in_port1 = "/axi/funnel@f8804000/in-ports/port@1/endpoint";
		funnel0_in_port2 = "/axi/funnel@f8804000/in-ports/port@2/endpoint";
		ptm0_out_port = "/axi/ptm@f889c000/out-ports/port/endpoint";
		ptm1_out_port = "/axi/ptm@f889d000/out-ports/port/endpoint";
		amba_pl = "/amba_pl";
		Audio_DMA_audio_formatter_0 = "/amba_pl/audio_formatter@43c00000";
		misc_clk_0 = "/amba_pl/misc_clk_0";
		Audio_DMA_i2s_receiver_0 = "/amba_pl/i2s_receiver@43c10000";
		misc_clk_1 = "/amba_pl/misc_clk_1";
		HDMI_0_axi_gpio_hdmi = "/amba_pl/gpio@41200000";
		HDMI_0_axi_vdma_0 = "/amba_pl/dma@43000000";
		HDMI_0_colorGainMain_axi_gpio_0 = "/amba_pl/gpio@41210000";
		HDMI_0_mixerMatrix_mixer_0 = "/amba_pl/mixer@43c50000";
		misc_clk_2 = "/amba_pl/misc_clk_2";
		HDMI_0_mixerMatrix_mixer_1 = "/amba_pl/mixer@43c60000";
		HDMI_0_mixerMatrix_mixer_2 = "/amba_pl/mixer@43c70000";
		HDMI_0_mixerMatrix_mixer_3 = "/amba_pl/mixer@43c80000";
		HDMI_0_mixerMatrix_mixer_4 = "/amba_pl/mixer@43c90000";
		HDMI_0_mixerMatrix_mixer_5 = "/amba_pl/mixer@43ca0000";
		HDMI_0_mixerMatrix_mixer_6 = "/amba_pl/mixer@43cb0000";
		HDMI_0_mixerMatrix_mixer_7 = "/amba_pl/mixer@43cc0000";
		HDMI_0_mixerMatrix_mixer_8 = "/amba_pl/mixer@43cd0000";
		HDMI_0_v_tc_0 = "/amba_pl/v_tc@43c20000";
		HDMI_1_axi_gpio_hdmi = "/amba_pl/gpio@41220000";
		HDMI_1_axi_vdma_0 = "/amba_pl/dma@43010000";
		HDMI_1_colorGainMain_axi_gain_1 = "/amba_pl/gpio@41230000";
		HDMI_1_v_tc_0 = "/amba_pl/v_tc@43c30000";
		axi_dynclk_0 = "/amba_pl/axi_dynclk@43c40000";
		hdmi_fb0 = "/framebuffer0@0x08000000";
	};
};
